# max32690 register map
Vendor: Maxim-Integrated; Series: ARMCM4; File version: 1.2
CPU: CM4 r2p1, little endian, MPU, FPU, 3 interrupt priority bits
Registers are 32-bit, read-write, reset 0x0 unless marked. A register's access mark holds for its fields unless they carry their own. Offsets are from the block's base; [hi:lo] are bit positions; {n}, {i} and the like mark numbered series; 'fields as' and 'values as' point back to an identical list.

## LPCMP — Low Power Comparator
Base 0x40088000
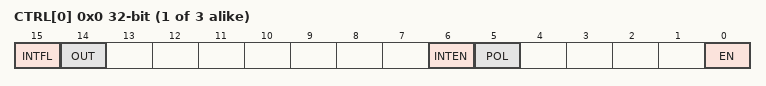
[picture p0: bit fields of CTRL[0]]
{0x0+4i} CTRL[{i}] (i=0..2) — Comparator Control Register.
  [15] INTFL — IRQ Flag
  [14] OUT — Raw Compartor Input.
  [6] INTEN — IRQ Enable.
  [5] POL — Polarity Select
  [0] EN — Comparator Enable.

## LPGCR — Low Power Global Control.
Base 0x40080000
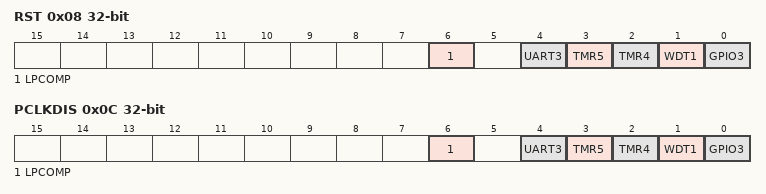
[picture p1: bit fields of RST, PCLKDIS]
0x08 RST — Low Power Reset Register.
  [all] fields
    0=reset_done (Reset complete.); 1=busy (Starts Reset or indicates reset in progress.)
  [6] LPCOMP — Low Power Comparator Reset.
  [4] UART3 — Low Power UART 3 Reset.
  [3] TMR5 — Low Power Timer 5 Reset.
  [2] TMR4 — Low Power Timer 4 Reset.
  [1] WDT1 — Low Power Watchdog Timer 1 Reset.
  [0] GPIO3 — Low Power GPIO 3 Reset.
0x0C PCLKDIS — Low Power Peripheral Clock Disable Register.
  [all] fields
    0=en (enable it.); 1=dis (disable it.)
  [6] LPCOMP — Low Power Comparator Clock Disable.
  [4] UART3 — Low Power UART 3 Clock Disable.
  [3] TMR5 — Low Power Timer 5 Clock Disable.
  [2] TMR4 — Low Power Timer 4 Clock Disable.
  [1] WDT1 — Low Power Watchdog 1 Clock Disable.
  [0] GPIO3 — Low Power GPIO 3 Clock Disable.

## MCR — Misc Control.
Base 0x40006C00
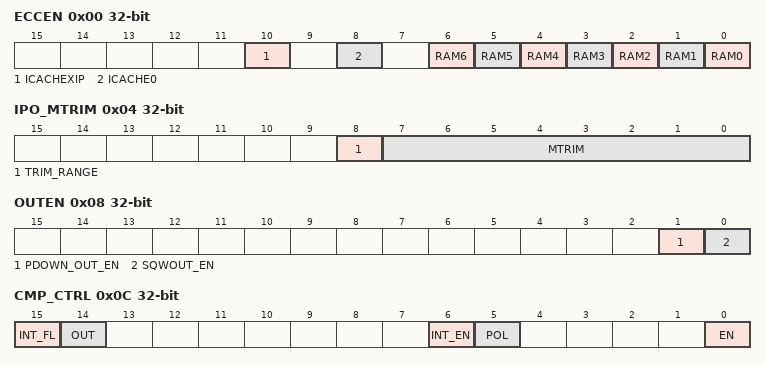
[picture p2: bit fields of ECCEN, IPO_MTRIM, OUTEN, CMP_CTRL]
0x00 ECCEN — ECC Enable Register
  [all] fields
    0=dis (disabled.); 1=en (enabled.)
  [10] ICACHEXIP — ECC ICACHE XIP Enable.
  [8] ICACHE0 — ECC ICACHE0 Enable.
  [n] RAM{n} (n=0..6) — ECC System RAM{n} Enable.
0x04 IPO_MTRIM — IPO Manual Register
  [8] TRIM_RANGE — Trim Range Select.
  [7:0] MTRIM — Manual Trim Value.
0x08 OUTEN — Output Enable Register
  [1] PDOWN_OUT_EN — Power Down Output Enable.
  [0] SQWOUT_EN — Square Wave Output Enable.
0x0C CMP_CTRL — Comparator Control Register.
  [15] INT_FL — IRQ Flag
  [14] OUT — Comparator Output State.
  [6] INT_EN — IRQ Enable.
  [5] POL — Polarity Select
  [0] EN — Comparator Enable.
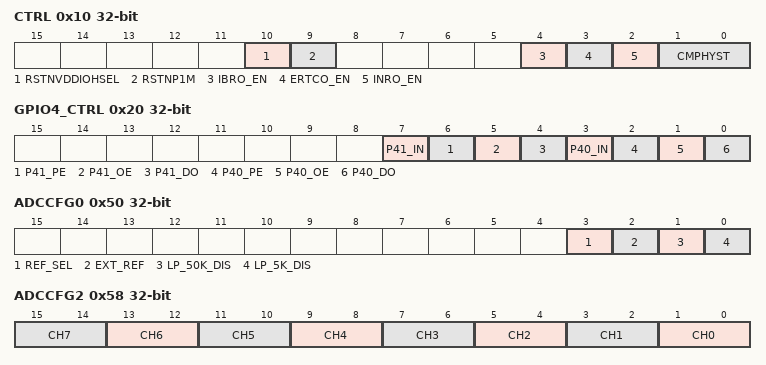
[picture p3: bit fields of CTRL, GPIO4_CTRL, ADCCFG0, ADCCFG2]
0x10 CTRL — Miscellaneous Control Register.
  [10] RSTNVDDIOHSEL — RSTNVFFIOHSEL
  [9] RSTNP1M
  [4] IBRO_EN — IBRO Enable.
  [3] ERTCO_EN — ERTCO Enable.
  [2] INRO_EN — INRO Enable.
  [1:0] CMPHYST — Comparator HYST.
0x20 GPIO4_CTRL — GPIO4 Pin Control Register.
  [7] P41_IN — GPIO4 Pin 1 Input Status.
  [6] P41_PE — GPIO4 Pin 1 Pull-up Enable.
  [5] P41_OE — GPIO4 Pin 1 Output Enable.
  [4] P41_DO — GPIO4 Pin 1 Data Output.
  [3] P40_IN — GPIO4 Pin 0 Input Status.
  [2] P40_PE — GPIO4 Pin 0 Pull-up Enable.
  [1] P40_OE — GPIO4 Pin 0 Output Enable.
  [0] P40_DO — GPIO4 Pin 0 Data Output.
0x40 CWD0 — Code Word Data0
  [31:0] data — Code word Data0 the register retains its value while vregi supply present
0x44 CWD1 — Code Word Data1
  fields as CWD0
0x50 ADCCFG0 — ADC Config 0
  [3] REF_SEL — Internal Reference Select Option
  [2] EXT_REF — External Reference Select Option
  [1] LP_50K_DIS — Disable 50K divider optionin low power modes
  [0] LP_5K_DIS — Disable 5K divider optionin low power modes
0x54 ADCCFG1 — ADC Config 1
  [12:0] CHX_PU_DYN — ADC PU dynamic control
0x58 ADCCFG2 — ADC Config 2
  [all] fields
    0=div1; 1=div2_5k (5k ohom); 2=div2_50k (50k ohom)
  [2n+1:2n] CH{n} (n=0..7) — Divider option for ADC input channel {n}
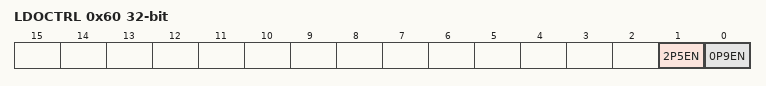
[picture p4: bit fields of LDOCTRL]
0x60 LDOCTRL — LDO Control
  [1] 2P5EN — LDO 2.5V Enable
  [0] 0P9EN — LDO 0.9V Enable

## OWM — 1-Wire Master Interface.
Base 0x4003D000
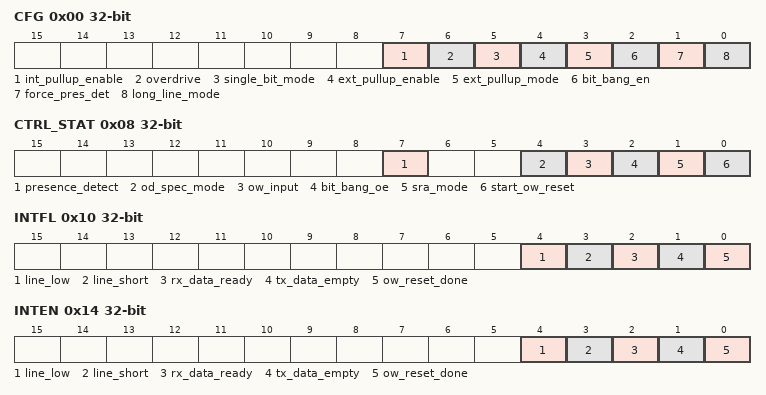
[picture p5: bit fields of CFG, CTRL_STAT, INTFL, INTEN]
0x00 CFG — 1-Wire Master Configuration.
  [7] int_pullup_enable — Enable intenral pullup.
  [6] overdrive — Enables overdrive speed for 1-Wire operations.
  [5] single_bit_mode — Enable Single Bit TX/RX Mode.
  [4] ext_pullup_enable — Enable External Pullup.
  [3] ext_pullup_mode — Provide an extra output control to control an external pullup.
  [2] bit_bang_en — Bit Bang Enable.
  [1] force_pres_det — Force Line During Presence Detect.
  [0] long_line_mode
0x04 CLK_DIV_1US — 1-Wire Master Clock Divisor.
  [7:0] divisor — Clock Divisor for 1Mhz.
0x08 CTRL_STAT — 1-Wire Master Control/Status.
  [7] presence_detect ro — Presence Pulse Detected.
  [4] od_spec_mode ro — Overdrive Spec Mode.
  [3] ow_input ro — OW Input State.
  [2] bit_bang_oe — Bit Bang Output Enable.
  [1] sra_mode
  [0] start_ow_reset
0x0C DATA — 1-Wire Master Data Buffer.
  [7:0] tx_rx — TX/RX Buffer.
0x10 INTFL — 1-Wire Master Interrupt Flags.
  [4] line_low — OW Line Low Detected Interrupt Flag.
  [3] line_short — OW Line Short Detected Interrupt Flag.
  [2] rx_data_ready — RX Data Ready Interrupt Flag
  [1] tx_data_empty — TX Data Empty Interrupt Flag.
  [0] ow_reset_done — OW Reset Sequence Completed.
0x14 INTEN — 1-Wire Master Interrupt Enables.
  [4] line_low write-1-clears — OW Line Low Detected Interrupt Enable.
  [3] line_short write-1-clears — OW Line Short Detected Interrupt Enable.
  [2] rx_data_ready write-1-clears — Rx Data Ready Interrupt Enable.
  [1] tx_data_empty write-1-clears — Tx Data Empty Interrupt Enable.
  [0] ow_reset_done write-1-clears — OW Reset Sequence Completed.
